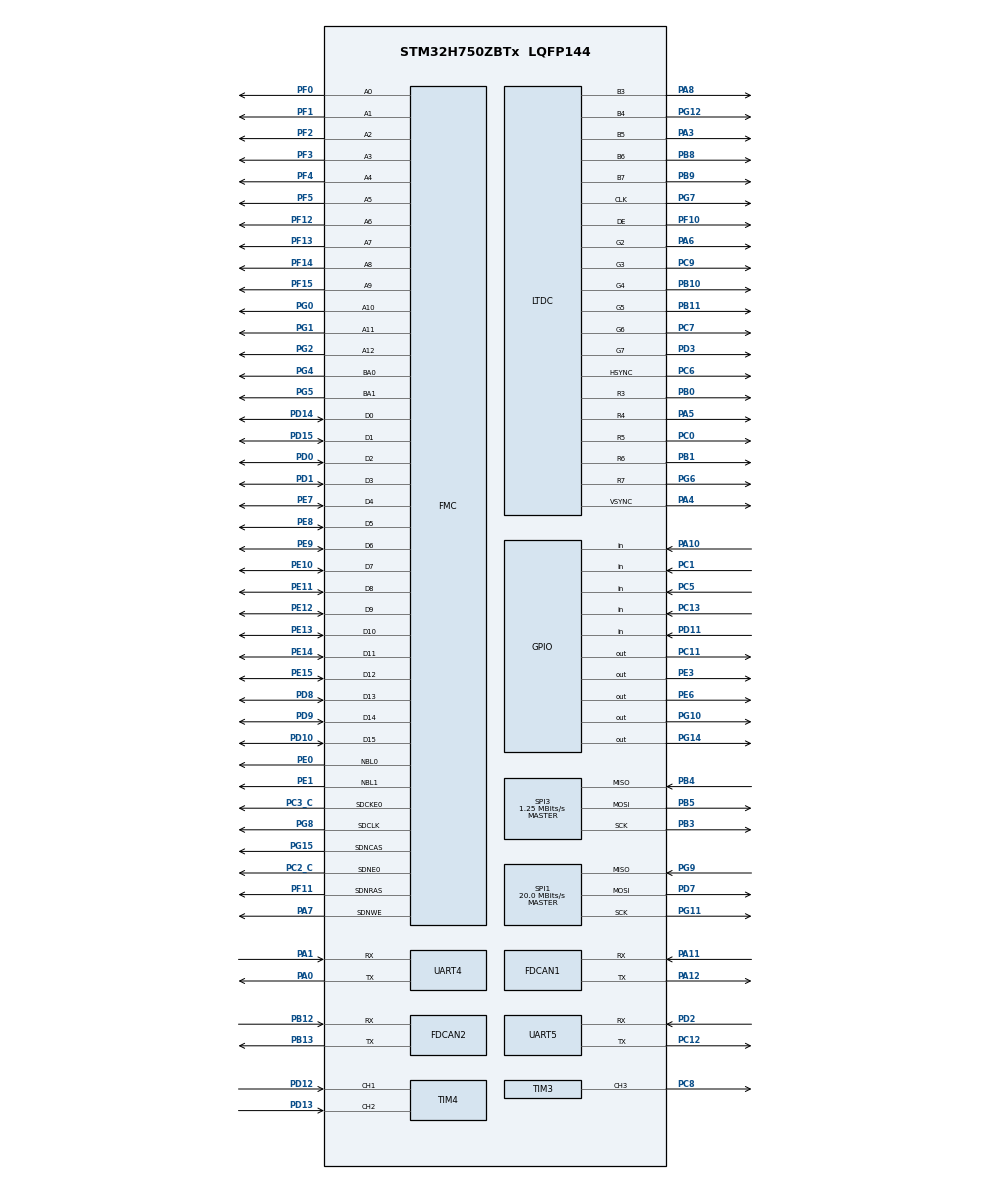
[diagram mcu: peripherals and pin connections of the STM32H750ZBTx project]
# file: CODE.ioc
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CORTEX_M7.CPU_DCache=Enabled
CORTEX_M7.CPU_ICache=Enabled
DMA2D.ColorMode=DMA2D_OUTPUT_RGB565
FDCAN1.AutoRetransmission=ENABLE
FDCAN1.CalculateBaudRateNominal=1000000
FDCAN1.CalculateTimeBitNominal=1000
FDCAN1.CalculateTimeQuantumNominal=25.0
FDCAN1.DataPrescaler=2
FDCAN1.DataSyncJumpWidth=1
FDCAN1.DataTimeSeg1=31
FDCAN1.DataTimeSeg2=8
FDCAN1.MessageRAMOffset=0
FDCAN1.NominalPrescaler=2
FDCAN1.NominalSyncJumpWidth=1
FDCAN1.NominalTimeSeg1=31
FDCAN1.NominalTimeSeg2=8
FDCAN1.ProtocolException=DISABLE
FDCAN1.RxFifo0ElmtsNbr=3
FDCAN1.StdFiltersNbr=1
FDCAN1.TxFifoQueueElmtsNbr=3
FDCAN2.AutoRetransmission=ENABLE
FDCAN2.CalculateBaudRateNominal=1000000
FDCAN2.CalculateTimeBitNominal=1000
FDCAN2.CalculateTimeQuantumNominal=25.0
FDCAN2.DataPrescaler=2
FDCAN2.DataTimeSeg1=31
FDCAN2.DataTimeSeg2=8
FDCAN2.MessageRAMOffset=0
FDCAN2.NominalPrescaler=2
FDCAN2.NominalTimeSeg1=31
FDCAN2.NominalTimeSeg2=8
FDCAN2.RxFifo0ElmtsNbr=3
FDCAN2.StdFiltersNbr=1
FDCAN2.TxFifoQueueElmtsNbr=3
FMC.CASLatency1=FMC_SDRAM_CAS_LATENCY_3
FMC.ColumnBitsNumber1=FMC_SDRAM_COLUMN_BITS_NUM_9
FMC.ExitSelfRefreshDelay1=7
FMC.LoadToActiveDelay1=2
FMC.RCDDelay1=2
FMC.RPDelay1=2
FMC.ReadBurst1=FMC_SDRAM_RBURST_ENABLE
FMC.ReadPipeDelay1=FMC_SDRAM_RPIPE_DELAY_1
FMC.ReadPipeDelay2=FMC_SDRAM_RPIPE_DELAY_1
FMC.RowCycleDelay1=7
FMC.RowCycleDelay2=7
FMC.SDClockPeriod1=FMC_SDRAM_CLOCK_PERIOD_2
FMC.SelfRefreshTime1=4
FMC.WriteRecoveryTime1=3
LTDC.ActiveH=272
LTDC.ActiveW=480
LTDC.Alpha_L0=255
LTDC.FBStartAdress_L0=0xC0000000
LTDC.HBP=40
LTDC.HFP=5
LTDC.HSync=1
LTDC.ImageHeight_L0=272
LTDC.ImageWidth_L0=480
LTDC.Layers=0
LTDC.PixelFormat_L0=LTDC_PIXEL_FORMAT_RGB565
LTDC.VBP=8
LTDC.VFP=8
LTDC.VSync=1
LTDC.WindowX1_L0=480
LTDC.WindowY1_L0=272
Mcu.Family=STM32H7
Mcu.Name=STM32H750ZBTx
Mcu.Package=LQFP144
NVIC.DMA2D_IRQn=true\:9\:0\:true\:false\:true\:true\:true\:true
NVIC.FDCAN1_IT0_IRQn=true\:0\:0\:false\:false\:true\:true\:true\:true
NVIC.FDCAN2_IT0_IRQn=true\:0\:0\:false\:false\:true\:true\:true\:true
NVIC.LTDC_IRQn=true\:9\:0\:true\:false\:true\:true\:true\:true
NVIC.PriorityGroup=NVIC_PRIORITYGROUP_4
PA0.Mode=Asynchronous
PA0.Signal=UART4_TX
PA1.Mode=Asynchronous
PA1.Signal=UART4_RX
PA10.GPIO_PuPd=GPIO_PULLUP
PA10.Signal=GPIO_Input
PA11.Mode=FDCAN_Activate
PA11.Signal=FDCAN1_RX
PA12.Mode=FDCAN_Activate
PA12.Signal=FDCAN1_TX
PA3.GPIO_Speed=GPIO_SPEED_FREQ_VERY_HIGH
PA3.Mode=RGB565
PA3.Signal=LTDC_B5
PA4.GPIO_Speed=GPIO_SPEED_FREQ_VERY_HIGH
PA4.Mode=RGB565
PA4.Signal=LTDC_VSYNC
PA5.GPIO_Speed=GPIO_SPEED_FREQ_VERY_HIGH
PA5.Mode=RGB565
PA5.Signal=LTDC_R4
PA6.GPIO_Speed=GPIO_SPEED_FREQ_VERY_HIGH
PA6.Mode=RGB565
PA6.Signal=LTDC_G2
PA7.Signal=FMC_SDNWE
PA8.GPIO_Speed=GPIO_SPEED_FREQ_VERY_HIGH
PA8.Mode=RGB565
PA8.Signal=LTDC_B3
PB0.GPIO_Speed=GPIO_SPEED_FREQ_VERY_HIGH
PB0.Mode=RGB565
PB0.Signal=LTDC_R3
PB1.GPIO_Speed=GPIO_SPEED_FREQ_VERY_HIGH
PB1.Mode=RGB565
PB1.Signal=LTDC_R6
PB10.GPIO_Speed=GPIO_SPEED_FREQ_VERY_HIGH
PB10.Mode=RGB565
PB10.Signal=LTDC_G4
PB11.GPIO_Speed=GPIO_SPEED_FREQ_VERY_HIGH
PB11.Mode=RGB565
PB11.Signal=LTDC_G5
PB12.Mode=FDCAN_Activate
PB12.Signal=FDCAN2_RX
PB13.Mode=FDCAN_Activate
PB13.Signal=FDCAN2_TX
PB3\ (JTDO/TRACESWO).Mode=Full_Duplex_Master
PB3\ (JTDO/TRACESWO).Signal=SPI3_SCK
PB4\ (NJTRST).Mode=Full_Duplex_Master
PB4\ (NJTRST).Signal=SPI3_MISO
PB5.Mode=Full_Duplex_Master
PB5.Signal=SPI3_MOSI
PB8.GPIO_FM8=SYSCFG_PMCR_I2C_PB8_FMP
PB8.GPIO_Speed=GPIO_SPEED_FREQ_VERY_HIGH
PB8.Mode=RGB565
PB8.Signal=LTDC_B6
PB9.GPIO_FM9=SYSCFG_PMCR_I2C_PB9_FMP
PB9.GPIO_Speed=GPIO_SPEED_FREQ_VERY_HIGH
PB9.Mode=RGB565
PB9.Signal=LTDC_B7
PC0.GPIO_Speed=GPIO_SPEED_FREQ_VERY_HIGH
PC0.Mode=RGB565
PC0.Signal=LTDC_R5
PC1.GPIO_PuPd=GPIO_PULLUP
PC1.Signal=GPIO_Input
PC11.GPIO_Speed=GPIO_SPEED_FREQ_VERY_HIGH
PC11.PinState=GPIO_PIN_SET
PC11.Signal=GPIO_Output
PC12.Mode=Asynchronous
PC12.Signal=UART5_TX
PC13.GPIO_PuPd=GPIO_PULLUP
PC13.Signal=GPIO_Input
PC2_C.Mode=SdramChipSelect1_1
PC2_C.Signal=FMC_SDNE0
PC3_C.Mode=SdramChipSelect1_1
PC3_C.Signal=FMC_SDCKE0
PC5.GPIO_PuPd=GPIO_PULLDOWN
PC5.Signal=GPIO_Input
PC6.GPIO_Speed=GPIO_SPEED_FREQ_VERY_HIGH
PC6.Mode=RGB565
PC6.Signal=LTDC_HSYNC
PC7.GPIO_Speed=GPIO_SPEED_FREQ_VERY_HIGH
PC7.Mode=RGB565
PC7.Signal=LTDC_G6
PC8.GPIO_Speed=GPIO_SPEED_FREQ_HIGH
PC8.Signal=S_TIM3_CH3
PC9.GPIO_Speed=GPIO_SPEED_FREQ_VERY_HIGH
PC9.Mode=RGB565
PC9.Signal=LTDC_G3
PD0.Signal=FMC_D2_DA2
PD1.Signal=FMC_D3_DA3
PD10.Signal=FMC_D15_DA15
PD11.GPIO_PuPd=GPIO_NOPULL
PD11.Signal=GPIO_Input
PD12.Signal=S_TIM4_CH1
PD13.Signal=S_TIM4_CH2
PD14.Signal=FMC_D0_DA0
PD15.Signal=FMC_D1_DA1
PD2.Mode=Asynchronous
PD2.Signal=UART5_RX
PD3.GPIO_Speed=GPIO_SPEED_FREQ_VERY_HIGH
PD3.Mode=RGB565
PD3.Signal=LTDC_G7
PD7.Mode=Full_Duplex_Master
PD7.Signal=SPI1_MOSI
PD8.Signal=FMC_D13_DA13
PD9.Signal=FMC_D14_DA14
PE0.Signal=FMC_NBL0
PE1.Signal=FMC_NBL1
PE10.Signal=FMC_D7_DA7
PE11.Signal=FMC_D8_DA8
PE12.Signal=FMC_D9_DA9
PE13.Signal=FMC_D10_DA10
PE14.Signal=FMC_D11_DA11
PE15.Signal=FMC_D12_DA12
PE3.GPIO_Speed=GPIO_SPEED_FREQ_VERY_HIGH
PE3.Signal=GPIO_Output
PE6.GPIO_PuPd=GPIO_PULLUP
PE6.Signal=GPIO_Output
PE7.Signal=FMC_D4_DA4
PE8.Signal=FMC_D5_DA5
PE9.Signal=FMC_D6_DA6
PF0.Signal=FMC_A0
PF1.Signal=FMC_A1
PF10.GPIO_Speed=GPIO_SPEED_FREQ_VERY_HIGH
PF10.Mode=RGB565
PF10.Signal=LTDC_DE
PF11.Signal=FMC_SDNRAS
PF12.Signal=FMC_A6
PF13.Signal=FMC_A7
PF14.Signal=FMC_A8
PF15.Signal=FMC_A9
PF2.Signal=FMC_A2
PF3.Signal=FMC_A3
PF4.Signal=FMC_A4
PF5.Signal=FMC_A5
PG0.Signal=FMC_A10
PG1.Signal=FMC_A11
PG10.Signal=GPIO_Output
PG11.Mode=Full_Duplex_Master
PG11.Signal=SPI1_SCK
PG12.GPIO_Speed=GPIO_SPEED_FREQ_VERY_HIGH
PG12.Mode=RGB565
PG12.Signal=LTDC_B4
PG14.GPIO_PuPd=GPIO_PULLUP
PG14.GPIO_Speed=GPIO_SPEED_FREQ_VERY_HIGH
PG14.PinState=GPIO_PIN_SET
PG14.Signal=GPIO_Output
PG15.Signal=FMC_SDNCAS
PG2.Signal=FMC_A12
PG4.Signal=FMC_A14_BA0
PG5.Signal=FMC_A15_BA1
PG6.GPIO_Speed=GPIO_SPEED_FREQ_VERY_HIGH
PG6.Mode=RGB565
PG6.Signal=LTDC_R7
PG7.GPIO_Speed=GPIO_SPEED_FREQ_VERY_HIGH
PG7.Mode=RGB565
PG7.Signal=LTDC_CLK
PG8.Signal=FMC_SDCLK
PG9.Mode=Full_Duplex_Master
PG9.Signal=SPI1_MISO
PH0-OSC_IN\ (PH0).Mode=HSE-External-Oscillator
PH0-OSC_IN\ (PH0).Signal=RCC_OSC_IN
PH1-OSC_OUT\ (PH1).Mode=HSE-External-Oscillator
PH1-OSC_OUT\ (PH1).Signal=RCC_OSC_OUT
ProjectManager.HeapSize=0x200
ProjectManager.StackSize=0x800
ProjectManager.TargetToolchain=MDK-ARM V5.27
RCC.ADCFreq_Value=50390625
RCC.APB1Freq_Value=100000000
RCC.APB2Freq_Value=100000000
RCC.APB3Freq_Value=100000000
RCC.APB4Freq_Value=100000000
RCC.CortexFreq_Value=400000000
RCC.D1PPRE=RCC_APB3_DIV2
RCC.D2PPRE1=RCC_APB1_DIV2
RCC.D2PPRE2=RCC_APB2_DIV2
RCC.D3PPRE=RCC_APB4_DIV2
RCC.DIVM1=2
RCC.DIVM3=25
RCC.DIVN1=64
RCC.DIVN3=180
RCC.DIVQ1=10
RCC.DIVR3=20
RCC.HCLKFreq_Value=200000000
RCC.HPRE=RCC_HCLK_DIV2
RCC.PLL2FRACN=0
RCC.PLL3FRACN=0
RCC.PLLFRACN=0
RCC.PLLSourceVirtual=RCC_PLLSOURCE_HSE
RCC.SYSCLKFreq_VALUE=400000000
RCC.SYSCLKSource=RCC_SYSCLKSOURCE_PLLCLK
RCC.USBFreq_Value=80000000
SH.FMC_A0.0=FMC_A0,13b-sda1
SH.FMC_A1.0=FMC_A1,13b-sda1
SH.FMC_A10.0=FMC_A10,13b-sda1
SH.FMC_A11.0=FMC_A11,13b-sda1
SH.FMC_A12.0=FMC_A12,13b-sda1
SH.FMC_A14_BA0.0=FMC_BA0,FourSdramBanks1
SH.FMC_A15_BA1.0=FMC_BA1,FourSdramBanks1
SH.FMC_A2.0=FMC_A2,13b-sda1
SH.FMC_A3.0=FMC_A3,13b-sda1
SH.FMC_A4.0=FMC_A4,13b-sda1
SH.FMC_A5.0=FMC_A5,13b-sda1
SH.FMC_A6.0=FMC_A6,13b-sda1
SH.FMC_A7.0=FMC_A7,13b-sda1
SH.FMC_A8.0=FMC_A8,13b-sda1
SH.FMC_A9.0=FMC_A9,13b-sda1
SH.FMC_D0_DA0.0=FMC_D0,sd-16b-d1
SH.FMC_D10_DA10.0=FMC_D10,sd-16b-d1
SH.FMC_D11_DA11.0=FMC_D11,sd-16b-d1
SH.FMC_D12_DA12.0=FMC_D12,sd-16b-d1
SH.FMC_D13_DA13.0=FMC_D13,sd-16b-d1
SH.FMC_D14_DA14.0=FMC_D14,sd-16b-d1
SH.FMC_D15_DA15.0=FMC_D15,sd-16b-d1
SH.FMC_D1_DA1.0=FMC_D1,sd-16b-d1
SH.FMC_D2_DA2.0=FMC_D2,sd-16b-d1
SH.FMC_D3_DA3.0=FMC_D3,sd-16b-d1
SH.FMC_D4_DA4.0=FMC_D4,sd-16b-d1
SH.FMC_D5_DA5.0=FMC_D5,sd-16b-d1
SH.FMC_D6_DA6.0=FMC_D6,sd-16b-d1
SH.FMC_D7_DA7.0=FMC_D7,sd-16b-d1
SH.FMC_D8_DA8.0=FMC_D8,sd-16b-d1
SH.FMC_D9_DA9.0=FMC_D9,sd-16b-d1
SH.FMC_NBL0.0=FMC_NBL0,Sd2ByteEnable1
SH.FMC_NBL1.0=FMC_NBL1,Sd2ByteEnable1
SH.FMC_SDCLK.0=FMC_SDCLK,13b-sda1
SH.FMC_SDNCAS.0=FMC_SDNCAS,13b-sda1
SH.FMC_SDNRAS.0=FMC_SDNRAS,13b-sda1
SH.FMC_SDNWE.0=FMC_SDNWE,13b-sda1
SH.S_TIM3_CH3.0=TIM3_CH3,PWM Generation3 CH3
SH.S_TIM4_CH1.0=TIM4_CH1,Encoder_Interface
SH.S_TIM4_CH2.0=TIM4_CH2,Encoder_Interface
SPI1.BaudRatePrescaler=SPI_BAUDRATEPRESCALER_4
SPI1.CLKPolarity=SPI_POLARITY_LOW
SPI1.CalculateBaudRate=20.0 MBits/s
SPI1.DataSize=SPI_DATASIZE_8BIT
SPI1.Direction=SPI_DIRECTION_2LINES
SPI1.Mode=SPI_MODE_MASTER
SPI1.VirtualType=VM_MASTER
SPI3.BaudRatePrescaler=SPI_BAUDRATEPRESCALER_64
SPI3.CalculateBaudRate=1.25 MBits/s
SPI3.DataSize=SPI_DATASIZE_8BIT
SPI3.Direction=SPI_DIRECTION_2LINES
SPI3.Mode=SPI_MODE_MASTER
SPI3.VirtualType=VM_MASTER
TIM3.Channel-PWM\ Generation3\ CH3=TIM_CHANNEL_3
TIM3.Period=19999
TIM3.Prescaler=9
TIM3.Pulse-PWM\ Generation3\ CH3=5000
TIM4.EncoderMode=TIM_ENCODERMODE_TI12
TIM4.IC1Filter=0x0F
TIM4.IC2Filter=0x0F
UART4.FIFOMode=FIFOMODE_ENABLE
UART4.RXFIFOThreshold=RXFIFO_THRESHOLD_1EIGHTHFULL
UART4.TXFIFOThreshold=TXFIFO_THRESHOLD_1EIGHTHFULL
UART5.DMADisableonRxErrorParam=UART_ADVFEATURE_DMA_DISABLEONRXERROR
UART5.FIFOMode=FIFOMODE_DISABLE
UART5.RXFIFOThreshold=RXFIFO_THRESHOLD_1EIGHTHFULL
UART5.TXFIFOThreshold=TXFIFO_THRESHOLD_1EIGHTHFULL
VP_DMA2D_VS_DMA2D.Mode=DMA2D_Activate
VP_RTC_VS_RTC_Activate.Mode=RTC_Enabled
board=custom

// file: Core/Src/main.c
/* USER CODE BEGIN Header */
/**
  ******************************************************************************
  * @file           : main.c
  * @brief          : Main program body
  ******************************************************************************
  * @attention
  *
  * Copyright (c) 2023 STMicroelectronics.
  * All rights reserved.
  *
  * This software is licensed under terms that can be found in the LICENSE file
  * in the root directory of this software component.
  * If no LICENSE file comes with this software, it is provided AS-IS.
  *
  ******************************************************************************
  */
/* USER CODE END Header */
#include "main.h"
#include "dma2d.h"
#include "fdcan.h"
#include "ltdc.h"
#include "rtc.h"
#include "spi.h"
#include "tim.h"
#include "usart.h"
#include "gpio.h"
#include "fmc.h"

/* USER CODE BEGIN Includes */
#include <stdio.h>
#include "string.h"

#include "bsp_lcd.h"
#include "bsp_touch.h"
#include "bsp_mx25l_spi.h"
#include "bsp_dcan.h"
#include "bsp_sdram.h"
#include "bsp_qspi_flash.h"
#include "bsp_uart.h"
#include "bsp_encoder.h"
#include "bsp_iic.h"
#include "bsp_gt911.h"
#include "bsp_TouchSet.h"

#include "app_version.h"
#include "app_cmd.h"
#include "app_config.h"
#include "app_pid.h"
#include "app_balanceRoll_code.h"
#include "app_DischargeSystem.h"
#include "app_RowknifeSystem.h"
#include "app_delta_servo.h"

#include "lvgl.h"
#include "lv_port_disp_template.h"
#include "lv_port_indev_template.h"
#include "lv_demo_stress.h"
#include "lv_demo_widgets.h"
#include "lv_demo_music.h"

#include "ui.h"
#include "ui_my_deal.h"

#include "p_set.h"

/* USER CODE END Includes */

/* USER CODE BEGIN PTD */
unsigned char G_timer_1ms_wr = 0;
unsigned char G_timer_1ms_rd = 0;
const unsigned int G_app_flag __attribute__((at(0x90001000))) = 0xE8280750;
const unsigned char G_app_version[4] __attribute__((at(0x90001004))) = {APP_VERSION_H, APP_VERSION_L, APP_VERSION_M, APP_VERSION_S};
/* USER CODE END PTD */

void SystemClock_Config(void);

/* USER CODE BEGIN 0 */
/********************************************************************************/

//定义_sys_exit()以避免使用半主机模式
void _sys_exit(int x)
{
	x = x;
}

void delay_us(int us)
{
	int count;
	int i;
	for (count = 0; count < us; count++)
	{
		for (i = 0; i < 13; i++)
		{
			__nop();
		}
	}
}

/*****************************************************************
BSP_init: 所有的BSP驱动初始化函数调用
******************************************************************/
void BSP_init(void)
{
    BSP_LCD_init();
    BSP_UART_init();
	BSP_SDRAM_init();
	MX25L_SPI_init();
    BSP_TouchInit();
    bsp_can_int();
//	BSP_QSPI_FLASH_init();
	BSP_ENCODER_init();
	BSP_SDRAM_test();

	lv_init();
	lv_port_disp_init();
	lv_port_indev_init();
}
/*****************************************************************
APP_init: 所有的APP初始化函数调用
******************************************************************/
void APP_init(void)
{
	ui_init();
	UI_my_deal_init();

	APP_CONFIG_load();
}

void MAIN_timer_1ms_Handler(void)
{
	G_timer_1ms_wr++;
    Pretr_RealTimeing_setPage();
    appRowKnifeRealTimeing();
//    Encode_handle.ReadIntervalTime++;
    BSP_TOUCH_loop_1ms();
	lv_tick_inc(1);
}

void MAIN_loop_1ms(void)
{
	static int timer_100ms_count = 0;
	static int timer_5ms_count = 0;

	timer_100ms_count++;

	if (timer_100ms_count >= 500)
	{
		timer_100ms_count = 0;
		HAL_GPIO_TogglePin(GPIOE, GPIO_PIN_3);
	}
	timer_5ms_count++;
	if (timer_5ms_count >= 5)
	{
		timer_5ms_count = 0;
		lv_timer_handler();
	}
}

void PeriphCommonClock_Config(void);

/* USER CODE END 0 */

int main(void)
{
  /* USER CODE BEGIN 1 */
   SCB->VTOR = QSPI_BASE;
  /* USER CODE END 1 */

  /* Enable I-Cache---------------------------------------------------------*/
  SCB_EnableICache();

  /* Enable D-Cache---------------------------------------------------------*/
  SCB_EnableDCache();

  /* MCU Configuration--------------------------------------------------------*/

  /* Reset of all peripherals, Initializes the Flash interface and the Systick. */
  HAL_Init();

  /* USER CODE BEGIN Init */
  SCB->CACR |= SCB_CACR_FORCEWT_Msk;
  /* USER CODE END Init */

  /* Configure the system clock */
  SystemClock_Config();

  /* USER CODE BEGIN SysInit */
/* Configure the peripherals common clocks */
  PeriphCommonClock_Config();
  /* USER CODE END SysInit */

  /* Initialize all configured peripherals */
  MX_GPIO_Init();
  MX_UART4_Init();
  MX_LTDC_Init();
  MX_DMA2D_Init();
  MX_SPI1_Init();
  MX_SPI3_Init();
  MX_FMC_Init();
  MX_FDCAN1_Init();
  MX_TIM4_Init();
  MX_FDCAN2_Init();
  MX_RTC_Init();
  MX_UART5_Init();
  MX_TIM3_Init();
  /* USER CODE BEGIN 2 */
  BSP_init();
  APP_init();

  DELTA_Servo_init();
  UI_StartRecovery();
  BSP_LCD_backlight_Brightness(_LCD_ScreenBrightness);
  Pretr_setInit();
  /* USER CODE END 2 */

  /* Infinite loop */
  while (1)
  {

    /* USER CODE BEGIN 3 */
      appRowKnifeSystemTask_loop();
      bsp_Can1SendQueueMsg_loop();
//      bsp_Can2SendQueueMsg_loop();
      Pretr_RealTimeRefreshShowloop_setPage();
      if (G_timer_1ms_wr != G_timer_1ms_rd)
	  {
		G_timer_1ms_rd++;
		MAIN_loop_1ms();
		UI_my_deal_loop_1ms();
	  }
      BSP_UART_loop();
  }
  /* USER CODE END 3 */
}

void SystemClock_Config(void)
{
  RCC_OscInitTypeDef RCC_OscInitStruct = {0};
  RCC_ClkInitTypeDef RCC_ClkInitStruct = {0};

  /** Supply configuration update enable
  */
  HAL_PWREx_ConfigSupply(PWR_LDO_SUPPLY);

  /** Configure the main internal regulator output voltage
  */
  __HAL_PWR_VOLTAGESCALING_CONFIG(PWR_REGULATOR_VOLTAGE_SCALE1);

  while(!__HAL_PWR_GET_FLAG(PWR_FLAG_VOSRDY)) {}

  /** Macro to configure the PLL clock source
  */
  __HAL_RCC_PLL_PLLSOURCE_CONFIG(RCC_PLLSOURCE_HSE);

  /** Initializes the RCC Oscillators according to the specified parameters
  * in the RCC_OscInitTypeDef structure.
  */
  RCC_OscInitStruct.OscillatorType = RCC_OSCILLATORTYPE_LSI|RCC_OSCILLATORTYPE_HSE;
  RCC_OscInitStruct.HSEState = RCC_HSE_ON;
  RCC_OscInitStruct.LSIState = RCC_LSI_ON;
  RCC_OscInitStruct.PLL.PLLState = RCC_PLL_ON;
  RCC_OscInitStruct.PLL.PLLSource = RCC_PLLSOURCE_HSE;
  RCC_OscInitStruct.PLL.PLLM = 2;
  RCC_OscInitStruct.PLL.PLLN = 64;
  RCC_OscInitStruct.PLL.PLLP = 2;
  RCC_OscInitStruct.PLL.PLLQ = 10;
  RCC_OscInitStruct.PLL.PLLR = 2;
  RCC_OscInitStruct.PLL.PLLRGE = RCC_PLL1VCIRANGE_3;
  RCC_OscInitStruct.PLL.PLLVCOSEL = RCC_PLL1VCOWIDE;
  RCC_OscInitStruct.PLL.PLLFRACN = 0;
  if (HAL_RCC_OscConfig(&RCC_OscInitStruct) != HAL_OK)
  {
    Error_Handler();
  }

  /** Initializes the CPU, AHB and APB buses clocks
  */
  RCC_ClkInitStruct.ClockType = RCC_CLOCKTYPE_HCLK|RCC_CLOCKTYPE_SYSCLK
                              |RCC_CLOCKTYPE_PCLK1|RCC_CLOCKTYPE_PCLK2
                              |RCC_CLOCKTYPE_D3PCLK1|RCC_CLOCKTYPE_D1PCLK1;
  RCC_ClkInitStruct.SYSCLKSource = RCC_SYSCLKSOURCE_PLLCLK;
  RCC_ClkInitStruct.SYSCLKDivider = RCC_SYSCLK_DIV1;
  RCC_ClkInitStruct.AHBCLKDivider = RCC_HCLK_DIV2;
  RCC_ClkInitStruct.APB3CLKDivider = RCC_APB3_DIV2;
  RCC_ClkInitStruct.APB1CLKDivider = RCC_APB1_DIV2;
  RCC_ClkInitStruct.APB2CLKDivider = RCC_APB2_DIV2;
  RCC_ClkInitStruct.APB4CLKDivider = RCC_APB4_DIV2;

  if (HAL_RCC_ClockConfig(&RCC_ClkInitStruct, FLASH_LATENCY_2) != HAL_OK)
  {
    Error_Handler();
  }
}

/* USER CODE BEGIN 4 */
/**
  * @brief Peripherals Common Clock Configuration
  * @retval None
  */
void PeriphCommonClock_Config(void)
{
  RCC_PeriphCLKInitTypeDef PeriphClkInitStruct = {0};

  /** Initializes the peripherals clock
  */
  PeriphClkInitStruct.PeriphClockSelection = RCC_PERIPHCLK_SPI3|RCC_PERIPHCLK_SPI1
                              |RCC_PERIPHCLK_LTDC;
  PeriphClkInitStruct.PLL3.PLL3M = 25;
  PeriphClkInitStruct.PLL3.PLL3N = 192;
  PeriphClkInitStruct.PLL3.PLL3P = 2;
  PeriphClkInitStruct.PLL3.PLL3Q = 4;
  PeriphClkInitStruct.PLL3.PLL3R = 20;
  PeriphClkInitStruct.PLL3.PLL3RGE = RCC_PLL3VCIRANGE_0;
  PeriphClkInitStruct.PLL3.PLL3VCOSEL = RCC_PLL3VCOWIDE;
  PeriphClkInitStruct.PLL3.PLL3FRACN = 0;
  PeriphClkInitStruct.Spi123ClockSelection = RCC_SPI123CLKSOURCE_PLL3;
  if (HAL_RCCEx_PeriphCLKConfig(&PeriphClkInitStruct) != HAL_OK)
  {
    Error_Handler();
  }
}

/* USER CODE END 4 */

void Error_Handler(void)
{
  __disable_irq();
  while (1)
  {
  }
}
